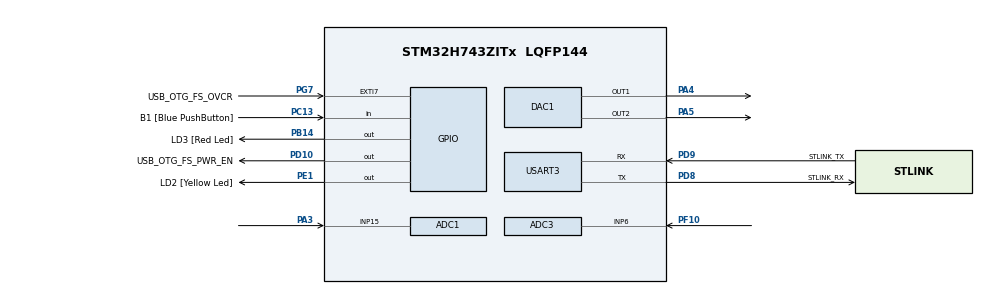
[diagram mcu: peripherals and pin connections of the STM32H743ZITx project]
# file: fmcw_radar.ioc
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ADC1.Channel-0\#ChannelRegularConversion=ADC_CHANNEL_15
ADC1.ConversionDataManagement=ADC_CONVERSIONDATA_DMA_CIRCULAR
ADC1.EnableInjectedConversion=DISABLE
ADC1.ExternalTrigConv=ADC_EXTERNALTRIG_T3_TRGO
ADC1.NbrOfConversion=1
ADC1.NbrOfConversionFlag=1
ADC1.OffsetNumber-0\#ChannelRegularConversion=ADC_OFFSET_NONE
ADC1.OffsetSignedSaturation-0\#ChannelRegularConversion=DISABLE
ADC1.Rank-0\#ChannelRegularConversion=1
ADC1.Resolution=ADC_RESOLUTION_12B
ADC1.SamplingTime-0\#ChannelRegularConversion=ADC_SAMPLETIME_1CYCLE_5
ADC1.master=1
ADC2.Channel-0\#ChannelRegularConversion=ADC_CHANNEL_DAC1CH1_ADC2
ADC2.ConversionDataManagement=ADC_CONVERSIONDATA_DMA_CIRCULAR
ADC2.ExternalTrigConv=ADC_EXTERNALTRIG_T4_TRGO
ADC2.NbrOfConversion=1
ADC2.NbrOfConversionFlag=1
ADC2.OffsetNumber-0\#ChannelRegularConversion=ADC_OFFSET_NONE
ADC2.OffsetSignedSaturation-0\#ChannelRegularConversion=DISABLE
ADC2.Rank-0\#ChannelRegularConversion=1
ADC2.SamplingTime-0\#ChannelRegularConversion=ADC_SAMPLETIME_1CYCLE_5
ADC3.Channel-0\#ChannelRegularConversion=ADC_CHANNEL_6
ADC3.ConversionDataManagement=ADC_CONVERSIONDATA_DMA_CIRCULAR
ADC3.ExternalTrigConv=ADC_EXTERNALTRIG_T3_TRGO
ADC3.NbrOfConversionFlag=1
ADC3.OffsetNumber-0\#ChannelRegularConversion=ADC_OFFSET_NONE
ADC3.OffsetSignedSaturation-0\#ChannelRegularConversion=DISABLE
ADC3.Rank-0\#ChannelRegularConversion=1
ADC3.SamplingTime-0\#ChannelRegularConversion=ADC_SAMPLETIME_1CYCLE_5
DAC1.DAC_Channel-DAC_OUT1_ExtAndInt=DAC_CHANNEL_1
DAC1.DAC_Channel-DAC_OUT2_ExtAndInt=DAC_CHANNEL_2
DAC1.DAC_Trigger-DAC_OUT1_ExtAndInt=DAC_TRIGGER_T4_TRGO
DAC1.DAC_Trigger-DAC_OUT2_ExtAndInt=DAC_TRIGGER_T4_TRGO
DAC1.TriangleAmplitude-DAC_OUT1_ExtAndInt=DAC_TRIANGLEAMPLITUDE_4095
DAC1.WaveGeneration-DAC_OUT1_ExtAndInt=TriangleWaveGeneration
DAC1.WaveGeneration-DAC_OUT2_ExtAndInt=DISABLE
Dma.ADC1.0.Direction=DMA_PERIPH_TO_MEMORY
Dma.ADC1.0.EventEnable=DISABLE
Dma.ADC1.0.FIFOMode=DMA_FIFOMODE_DISABLE
Dma.ADC1.0.Instance=DMA1_Stream0
Dma.ADC1.0.MemDataAlignment=DMA_MDATAALIGN_HALFWORD
Dma.ADC1.0.MemInc=DMA_MINC_ENABLE
Dma.ADC1.0.Mode=DMA_CIRCULAR
Dma.ADC1.0.PeriphDataAlignment=DMA_PDATAALIGN_HALFWORD
Dma.ADC1.0.PeriphInc=DMA_PINC_DISABLE
Dma.ADC1.0.Polarity=HAL_DMAMUX_REQ_GEN_RISING
Dma.ADC1.0.Priority=DMA_PRIORITY_LOW
Dma.ADC1.0.RequestNumber=1
Dma.ADC1.0.SignalID=NONE
Dma.ADC1.0.SyncEnable=DISABLE
Dma.ADC1.0.SyncPolarity=HAL_DMAMUX_SYNC_NO_EVENT
Dma.ADC1.0.SyncRequestNumber=1
Dma.ADC1.0.SyncSignalID=NONE
Dma.ADC2.2.Direction=DMA_PERIPH_TO_MEMORY
Dma.ADC2.2.EventEnable=DISABLE
Dma.ADC2.2.FIFOMode=DMA_FIFOMODE_DISABLE
Dma.ADC2.2.Instance=DMA2_Stream0
Dma.ADC2.2.MemDataAlignment=DMA_MDATAALIGN_HALFWORD
Dma.ADC2.2.MemInc=DMA_MINC_ENABLE
Dma.ADC2.2.Mode=DMA_CIRCULAR
Dma.ADC2.2.PeriphDataAlignment=DMA_PDATAALIGN_HALFWORD
Dma.ADC2.2.PeriphInc=DMA_PINC_DISABLE
Dma.ADC2.2.Polarity=HAL_DMAMUX_REQ_GEN_RISING
Dma.ADC2.2.Priority=DMA_PRIORITY_LOW
Dma.ADC2.2.RequestNumber=1
Dma.ADC2.2.SignalID=NONE
Dma.ADC2.2.SyncEnable=DISABLE
Dma.ADC2.2.SyncPolarity=HAL_DMAMUX_SYNC_NO_EVENT
Dma.ADC2.2.SyncRequestNumber=1
Dma.ADC2.2.SyncSignalID=NONE
Dma.ADC3.1.Direction=DMA_PERIPH_TO_MEMORY
Dma.ADC3.1.EventEnable=DISABLE
Dma.ADC3.1.FIFOMode=DMA_FIFOMODE_DISABLE
Dma.ADC3.1.Instance=DMA1_Stream2
Dma.ADC3.1.MemDataAlignment=DMA_MDATAALIGN_HALFWORD
Dma.ADC3.1.MemInc=DMA_MINC_ENABLE
Dma.ADC3.1.Mode=DMA_CIRCULAR
Dma.ADC3.1.PeriphDataAlignment=DMA_PDATAALIGN_HALFWORD
Dma.ADC3.1.PeriphInc=DMA_PINC_DISABLE
Dma.ADC3.1.Polarity=HAL_DMAMUX_REQ_GEN_RISING
Dma.ADC3.1.Priority=DMA_PRIORITY_LOW
Dma.ADC3.1.RequestNumber=1
Dma.ADC3.1.SignalID=NONE
Dma.ADC3.1.SyncEnable=DISABLE
Dma.ADC3.1.SyncPolarity=HAL_DMAMUX_SYNC_NO_EVENT
Dma.ADC3.1.SyncRequestNumber=1
Dma.ADC3.1.SyncSignalID=NONE
Dma.DAC1_CH2.3.Direction=DMA_MEMORY_TO_PERIPH
Dma.DAC1_CH2.3.EventEnable=DISABLE
Dma.DAC1_CH2.3.FIFOMode=DMA_FIFOMODE_DISABLE
Dma.DAC1_CH2.3.Instance=DMA1_Stream6
Dma.DAC1_CH2.3.MemDataAlignment=DMA_MDATAALIGN_HALFWORD
Dma.DAC1_CH2.3.MemInc=DMA_MINC_ENABLE
Dma.DAC1_CH2.3.Mode=DMA_CIRCULAR
Dma.DAC1_CH2.3.PeriphDataAlignment=DMA_PDATAALIGN_HALFWORD
Dma.DAC1_CH2.3.PeriphInc=DMA_PINC_DISABLE
Dma.DAC1_CH2.3.Polarity=HAL_DMAMUX_REQ_GEN_RISING
Dma.DAC1_CH2.3.Priority=DMA_PRIORITY_LOW
Dma.DAC1_CH2.3.RequestNumber=1
Dma.DAC1_CH2.3.SignalID=NONE
Dma.DAC1_CH2.3.SyncEnable=DISABLE
Dma.DAC1_CH2.3.SyncPolarity=HAL_DMAMUX_SYNC_NO_EVENT
Dma.DAC1_CH2.3.SyncRequestNumber=1
Dma.DAC1_CH2.3.SyncSignalID=NONE
Dma.Request0=ADC1
Dma.Request1=ADC3
Dma.Request2=ADC2
Dma.Request3=DAC1_CH2
Dma.Request4=USART3_TX
Dma.USART3_TX.4.Direction=DMA_MEMORY_TO_PERIPH
Dma.USART3_TX.4.EventEnable=DISABLE
Dma.USART3_TX.4.FIFOMode=DMA_FIFOMODE_DISABLE
Dma.USART3_TX.4.Instance=DMA1_Stream3
Dma.USART3_TX.4.MemDataAlignment=DMA_MDATAALIGN_BYTE
Dma.USART3_TX.4.MemInc=DMA_MINC_ENABLE
Dma.USART3_TX.4.Mode=DMA_CIRCULAR
Dma.USART3_TX.4.PeriphDataAlignment=DMA_PDATAALIGN_BYTE
Dma.USART3_TX.4.PeriphInc=DMA_PINC_DISABLE
Dma.USART3_TX.4.Polarity=HAL_DMAMUX_REQ_GEN_RISING
Dma.USART3_TX.4.Priority=DMA_PRIORITY_MEDIUM
Dma.USART3_TX.4.RequestNumber=1
Dma.USART3_TX.4.SignalID=NONE
Dma.USART3_TX.4.SyncEnable=DISABLE
Dma.USART3_TX.4.SyncPolarity=HAL_DMAMUX_SYNC_NO_EVENT
Dma.USART3_TX.4.SyncRequestNumber=1
Dma.USART3_TX.4.SyncSignalID=NONE
Mcu.Family=STM32H7
Mcu.Name=STM32H743ZITx
Mcu.Package=LQFP144
NVIC.DMA1_Stream0_IRQn=true\:0\:0\:false\:false\:true\:false\:true
NVIC.DMA1_Stream2_IRQn=true\:0\:0\:false\:false\:true\:false\:true
NVIC.DMA1_Stream3_IRQn=true\:0\:0\:false\:false\:true\:false\:true
NVIC.DMA1_Stream6_IRQn=true\:0\:0\:false\:false\:true\:false\:true
NVIC.DMA2_Stream0_IRQn=true\:0\:0\:false\:false\:true\:false\:true
NVIC.PriorityGroup=NVIC_PRIORITYGROUP_4
NVIC.USART3_IRQn=true\:0\:0\:false\:false\:true\:true\:true
PA1.Signal=ETH_REF_CLK
PA11.Signal=USB_OTG_FS_DM
PA12.Signal=USB_OTG_FS_DP
PA2.Signal=ETH_MDIO
PA3.Signal=ADCx_INP15
PA4.Signal=COMP_DAC11_group
PA5.Signal=COMP_DAC12_group
PA7.Signal=ETH_CRS_DV
PA8.Signal=USB_OTG_FS_SOF
PA9.Signal=USB_OTG_FS_VBUS
PB0.Signal=S_TIM3_CH3
PB13.Signal=ETH_TXD1
PB14.GPIO_Label=LD3 [Red Led]
PB14.Signal=GPIO_Output
PC1.Signal=ETH_MDC
PC13.GPIO_Label=B1 [Blue PushButton]
PC13.Signal=GPIO_Input
PC14-OSC32_IN\ (OSC32_IN).Mode=LSE-External-Oscillator
PC14-OSC32_IN\ (OSC32_IN).Signal=RCC_OSC32_IN
PC15-OSC32_OUT\ (OSC32_OUT).Mode=LSE-External-Oscillator
PC15-OSC32_OUT\ (OSC32_OUT).Signal=RCC_OSC32_OUT
PC4.Signal=ETH_RXD0
PC5.Signal=ETH_RXD1
PD10.GPIO_Label=USB_OTG_FS_PWR_EN
PD10.Signal=GPIO_Output
PD8.GPIO_Label=STLINK_RX
PD8.Mode=Asynchronous
PD8.Signal=USART3_TX
PD9.GPIO_Label=STLINK_TX
PD9.Mode=Asynchronous
PD9.Signal=USART3_RX
PE1.GPIO_Label=LD2 [Yellow Led]
PE1.Signal=GPIO_Output
PF10.Mode=IN6-Single-Ended
PF10.Signal=ADC3_INP6
PG11.Signal=ETH_TX_EN
PG13.Signal=ETH_TXD0
PG7.GPIO_Label=USB_OTG_FS_OVCR
PG7.Signal=GPXTI7
PH0-OSC_IN\ (PH0).Mode=HSE-External-Clock-Source
PH0-OSC_IN\ (PH0).Signal=RCC_OSC_IN
PH1-OSC_OUT\ (PH1).Signal=RCC_OSC_OUT
ProjectManager.HeapSize=0x200
ProjectManager.StackSize=0x400
ProjectManager.TargetToolchain=STM32CubeIDE
RCC.ADCFreq_Value=37500000
RCC.APB1Freq_Value=64000000
RCC.APB2Freq_Value=64000000
RCC.APB3Freq_Value=64000000
RCC.APB4Freq_Value=64000000
RCC.CortexFreq_Value=64000000
RCC.DIVM1=1
RCC.DIVM2=1
RCC.DIVN1=24
RCC.DIVN2=18
RCC.DIVP2=4
RCC.DIVQ1=4
RCC.HCLKFreq_Value=64000000
RCC.HSE_VALUE=8000000
RCC.PLL2FRACN=6144
RCC.PLLFRACN=0
RCC.PLLSourceVirtual=RCC_PLLSOURCE_HSE
RCC.PWR_Regulator_Voltage_Scale=PWR_REGULATOR_VOLTAGE_SCALE2
RCC.SYSCLKFreq_VALUE=64000000
RCC.USBFreq_Value=48000000
SH.ADCx_INP15.0=ADC1_INP15,IN15-Single-Ended
SH.COMP_DAC11_group.0=DAC1_OUT1,DAC_OUT1_ExtAndInt
SH.COMP_DAC12_group.0=DAC1_OUT2,DAC_OUT2_ExtAndInt
SH.S_TIM3_CH3.0=TIM3_CH3
TIM1.AutoReloadPreload=TIM_AUTORELOAD_PRELOAD_DISABLE
TIM1.Period=1
TIM1.Prescaler=0
TIM1.TIM_MasterOutputTrigger=TIM_TRGO_UPDATE
TIM1.TIM_MasterSlaveMode=TIM_MASTERSLAVEMODE_ENABLE
TIM3.Period=1250
TIM3.Prescaler=9
TIM3.TIM_MasterOutputTrigger=TIM_TRGO_UPDATE
TIM3.TIM_MasterSlaveMode=TIM_MASTERSLAVEMODE_ENABLE
TIM4.Period=390
TIM4.Prescaler=0
TIM4.TIM_MasterOutputTrigger=TIM_TRGO_UPDATE
TIM4.TIM_MasterSlaveMode=TIM_MASTERSLAVEMODE_ENABLE
USART3.VirtualMode-Asynchronous=VM_ASYNC
VP_ADC2_VS_DAC1_OUT1_L4.Mode=IN-DAC1-OUT1
VP_ADC3_Vref_Input.Mode=IN-Vrefint
VP_TIM1_VS_ClockSourceINT.Mode=Internal
VP_TIM3_VS_ClockSourceITR.Mode=TriggerSource_ITR0
VP_TIM3_VS_ControllerModeTrigger.Mode=Trigger Mode
VP_TIM4_VS_ClockSourceITR.Mode=TriggerSource_ITR0
VP_TIM4_VS_ControllerModeTrigger.Mode=Trigger Mode
board=NUCLEO-H743ZI2

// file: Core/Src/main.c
/* USER CODE BEGIN Header */
/**
  ******************************************************************************
  * @file           : main.c
  * @brief          : Main program body
  ******************************************************************************
  * @attention
  *
  * <h2><center>&copy; Copyright (c) 2021 STMicroelectronics.
  * All rights reserved.</center></h2>
  *
  * This software component is licensed by ST under BSD 3-Clause license,
  * the "License"; You may not use this file except in compliance with the
  * License. You may obtain a copy of the License at:
  *                        opensource.org/licenses/BSD-3-Clause
  *
  ******************************************************************************
  */
/* USER CODE END Header */
#include "main.h"
#include "adc.h"
#include "dac.h"
#include "dma.h"
#include "tim.h"
#include "usart.h"
#include "gpio.h"

/* USER CODE BEGIN Includes */
#include "radar.h"
/* USER CODE END Includes */

void SystemClock_Config(void);
void PeriphCommonClock_Config(void);

int main(void)
{

  /* MCU Configuration--------------------------------------------------------*/

  /* Reset of all peripherals, Initializes the Flash interface and the Systick. */
  HAL_Init();

  /* Configure the system clock */
  SystemClock_Config();

/* Configure the peripherals common clocks */
  PeriphCommonClock_Config();

  /* Initialize all configured peripherals */
  MX_GPIO_Init();
  MX_DMA_Init();
  MX_DAC1_Init();
  MX_TIM1_Init();
  MX_TIM3_Init();
  MX_USART3_UART_Init();
  MX_TIM4_Init();
  MX_ADC1_Init();
  MX_ADC3_Init();
  MX_ADC2_Init();
  /* USER CODE BEGIN 2 */
  HAL_Delay(1000);
  init_hardware();
  /* USER CODE END 2 */

  /* Infinite loop */
  /* USER CODE BEGIN WHILE */
  while (1)
  {
	  radar_routine();
    /* USER CODE END WHILE */

  }
}

void SystemClock_Config(void)
{
  RCC_OscInitTypeDef RCC_OscInitStruct = {0};
  RCC_ClkInitTypeDef RCC_ClkInitStruct = {0};

  /** Supply configuration update enable
  */
  HAL_PWREx_ConfigSupply(PWR_LDO_SUPPLY);
  /** Configure the main internal regulator output voltage
  */
  __HAL_PWR_VOLTAGESCALING_CONFIG(PWR_REGULATOR_VOLTAGE_SCALE2);

  while(!__HAL_PWR_GET_FLAG(PWR_FLAG_VOSRDY)) {}
  /** Macro to configure the PLL clock source
  */
  __HAL_RCC_PLL_PLLSOURCE_CONFIG(RCC_PLLSOURCE_HSE);
  /** Initializes the RCC Oscillators according to the specified parameters
  * in the RCC_OscInitTypeDef structure.
  */
  RCC_OscInitStruct.OscillatorType = RCC_OSCILLATORTYPE_HSI|RCC_OSCILLATORTYPE_HSE;
  RCC_OscInitStruct.HSEState = RCC_HSE_BYPASS;
  RCC_OscInitStruct.HSIState = RCC_HSI_DIV1;
  RCC_OscInitStruct.HSICalibrationValue = RCC_HSICALIBRATION_DEFAULT;
  RCC_OscInitStruct.PLL.PLLState = RCC_PLL_NONE;
  RCC_OscInitStruct.PLL.PLLSource = RCC_PLLSOURCE_HSE;
  if (HAL_RCC_OscConfig(&RCC_OscInitStruct) != HAL_OK)
  {
    Error_Handler();
  }
  /** Initializes the CPU, AHB and APB buses clocks
  */
  RCC_ClkInitStruct.ClockType = RCC_CLOCKTYPE_HCLK|RCC_CLOCKTYPE_SYSCLK
                              |RCC_CLOCKTYPE_PCLK1|RCC_CLOCKTYPE_PCLK2
                              |RCC_CLOCKTYPE_D3PCLK1|RCC_CLOCKTYPE_D1PCLK1;
  RCC_ClkInitStruct.SYSCLKSource = RCC_SYSCLKSOURCE_HSI;
  RCC_ClkInitStruct.SYSCLKDivider = RCC_SYSCLK_DIV1;
  RCC_ClkInitStruct.AHBCLKDivider = RCC_HCLK_DIV1;
  RCC_ClkInitStruct.APB3CLKDivider = RCC_APB3_DIV1;
  RCC_ClkInitStruct.APB1CLKDivider = RCC_APB1_DIV1;
  RCC_ClkInitStruct.APB2CLKDivider = RCC_APB2_DIV1;
  RCC_ClkInitStruct.APB4CLKDivider = RCC_APB4_DIV1;

  if (HAL_RCC_ClockConfig(&RCC_ClkInitStruct, FLASH_LATENCY_1) != HAL_OK)
  {
    Error_Handler();
  }
}

void PeriphCommonClock_Config(void)
{
  RCC_PeriphCLKInitTypeDef PeriphClkInitStruct = {0};

  /** Initializes the peripherals clock
  */
  PeriphClkInitStruct.PeriphClockSelection = RCC_PERIPHCLK_ADC;
  PeriphClkInitStruct.PLL2.PLL2M = 1;
  PeriphClkInitStruct.PLL2.PLL2N = 18;
  PeriphClkInitStruct.PLL2.PLL2P = 4;
  PeriphClkInitStruct.PLL2.PLL2Q = 2;
  PeriphClkInitStruct.PLL2.PLL2R = 2;
  PeriphClkInitStruct.PLL2.PLL2RGE = RCC_PLL2VCIRANGE_3;
  PeriphClkInitStruct.PLL2.PLL2VCOSEL = RCC_PLL2VCOMEDIUM;
  PeriphClkInitStruct.PLL2.PLL2FRACN = 6144;
  PeriphClkInitStruct.AdcClockSelection = RCC_ADCCLKSOURCE_PLL2;
  if (HAL_RCCEx_PeriphCLKConfig(&PeriphClkInitStruct) != HAL_OK)
  {
    Error_Handler();
  }
}

void Error_Handler(void)
{
  __disable_irq();
  while (1)
  {
  }
}

/************************ (C) COPYRIGHT STMicroelectronics *****END OF FILE****/
